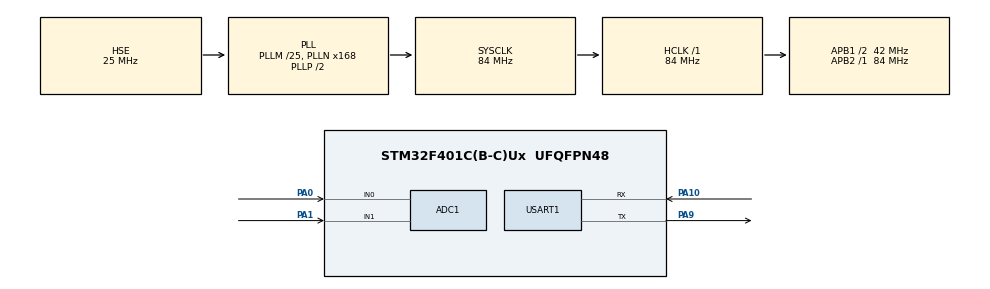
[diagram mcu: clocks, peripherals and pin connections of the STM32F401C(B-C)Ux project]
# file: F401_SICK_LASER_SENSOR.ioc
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ADC1.Channel-0\#ChannelRegularConversion=ADC_CHANNEL_0
ADC1.Channel-1\#ChannelRegularConversion=ADC_CHANNEL_1
ADC1.ContinuousConvMode=ENABLE
ADC1.NbrOfConversion=2
ADC1.NbrOfConversionFlag=1
ADC1.Rank-0\#ChannelRegularConversion=1
ADC1.Rank-1\#ChannelRegularConversion=2
ADC1.SamplingTime-0\#ChannelRegularConversion=ADC_SAMPLETIME_3CYCLES
ADC1.SamplingTime-1\#ChannelRegularConversion=ADC_SAMPLETIME_15CYCLES
ADC1.master=1
Dma.ADC1.0.Direction=DMA_PERIPH_TO_MEMORY
Dma.ADC1.0.FIFOMode=DMA_FIFOMODE_DISABLE
Dma.ADC1.0.Instance=DMA2_Stream0
Dma.ADC1.0.MemDataAlignment=DMA_MDATAALIGN_WORD
Dma.ADC1.0.MemInc=DMA_MINC_ENABLE
Dma.ADC1.0.Mode=DMA_CIRCULAR
Dma.ADC1.0.PeriphDataAlignment=DMA_PDATAALIGN_WORD
Dma.ADC1.0.PeriphInc=DMA_PINC_DISABLE
Dma.ADC1.0.Priority=DMA_PRIORITY_LOW
Dma.Request0=ADC1
Mcu.Family=STM32F4
Mcu.Name=STM32F401C(B-C)Ux
Mcu.Package=UFQFPN48
NVIC.ADC_IRQn=true\:0\:0\:false\:false\:true\:true\:true\:true
NVIC.DMA2_Stream0_IRQn=true\:0\:0\:false\:false\:true\:false\:true\:true
NVIC.PriorityGroup=NVIC_PRIORITYGROUP_4
PA0-WKUP.Signal=ADCx_IN0
PA1.Signal=ADCx_IN1
PA10.Mode=Asynchronous
PA10.Signal=USART1_RX
PA13.Mode=Serial_Wire
PA13.Signal=SYS_JTMS-SWDIO
PA14.Mode=Serial_Wire
PA14.Signal=SYS_JTCK-SWCLK
PA9.Mode=Asynchronous
PA9.Signal=USART1_TX
PH0\ -\ OSC_IN.Mode=HSE-External-Oscillator
PH0\ -\ OSC_IN.Signal=RCC_OSC_IN
PH1\ -\ OSC_OUT.Mode=HSE-External-Oscillator
PH1\ -\ OSC_OUT.Signal=RCC_OSC_OUT
ProjectManager.HeapSize=0x200
ProjectManager.StackSize=0x400
ProjectManager.TargetToolchain=STM32CubeIDE
RCC.48MHZClocksFreq_Value=42000000
RCC.AHBFreq_Value=84000000
RCC.APB1CLKDivider=RCC_HCLK_DIV2
RCC.APB1Freq_Value=42000000
RCC.APB1TimFreq_Value=84000000
RCC.APB2Freq_Value=84000000
RCC.APB2TimFreq_Value=84000000
RCC.CortexFreq_Value=84000000
RCC.HCLKFreq_Value=84000000
RCC.HSE_VALUE=25000000
RCC.HSI_VALUE=16000000
RCC.LSE_VALUE=32768
RCC.PLLM=25
RCC.PLLN=168
RCC.PLLSourceVirtual=RCC_PLLSOURCE_HSE
RCC.SYSCLKFreq_VALUE=84000000
RCC.SYSCLKSource=RCC_SYSCLKSOURCE_PLLCLK
RCC.VCOOutputFreq_Value=168000000
SH.ADCx_IN0.0=ADC1_IN0,IN0
SH.ADCx_IN1.0=ADC1_IN1,IN1
USART1.VirtualMode=VM_ASYNC
board=custom

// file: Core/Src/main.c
/* USER CODE BEGIN Header */
/**
  ******************************************************************************
  * @file           : main.c
  * @brief          : Main program body
  ******************************************************************************
  * @attention
  *
  * Copyright (c) 2024 STMicroelectronics.
  * All rights reserved.
  *
  * This software is licensed under terms that can be found in the LICENSE file
  * in the root directory of this software component.
  * If no LICENSE file comes with this software, it is provided AS-IS.
  *
  ******************************************************************************
  */
/* USER CODE END Header */
#include "main.h"
#include "adc.h"
#include "dma.h"
#include "usart.h"
#include "gpio.h"

/* USER CODE BEGIN Includes */

	float DISTANCE = 0;

/* USER CODE END Includes */

/* USER CODE BEGIN PV */

//	char msg[20];

/* USER CODE END PV */

void SystemClock_Config(void);

/* USER CODE BEGIN 0 */

		uint32_t ADC_SICK_SENSOR;
		uint32_t LASOR_SENSOR;

		/* INTERRUP MODE */

			/*

				void HAL_ADC_ConvCpltCallback(ADC_HandleTypeDef* hadc)
				{

				  ADC_SICK_SENSOR = HAL_ADC_GetValue(&hadc1);
				  // IF CONTINUOUS CONVERSION MODE IS DISABLED UNCOMMENT
				  // HAL_ADC_Start_IT (&hadc1);
				}

			*/

		/* DMA MODE */

			/*
				void HAL_ADC_ConvCpltCallback(ADC_HandleTypeDef* hadc)
				{

					ADC_SICK_SENSOR = LASOR_SENSOR; // STORE THE VALUE IN ADC_SICK_SENSOR

				}
			*/

/* USER CODE END 0 */

int main(void)
{

  /* MCU Configuration--------------------------------------------------------*/

  /* Reset of all peripherals, Initializes the Flash interface and the Systick. */
  HAL_Init();

  /* Configure the system clock */
  SystemClock_Config();

  /* Initialize all configured peripherals */
  MX_GPIO_Init();
  MX_DMA_Init();
  MX_ADC1_Init();
  MX_USART1_UART_Init();
  /* USER CODE BEGIN 2 */

	   /* INTERRUP MODE */

			  /*
				   HAL_ADC_Start_IT(&hadc1); // START TH DMA IN THE INTERRUP MODE
			  */

	   /* DMA MODE */

			   /*
				   HAL_ADC_Start_DMA(&hadc1, &LASOR_SENSOR, 1); // START IN DMA MODE AND WE ARE READ ONLY ONE CHANNEL OR ONE WORD
			   */

  /* USER CODE END 2 */

  /* Infinite loop */
  while (1)
  {

    /* USER CODE BEGIN 3 */

		  /* ADC MODE */

				  HAL_ADC_Start(&hadc1); /* START THE ADC */
				  HAL_ADC_PollForConversion(&hadc1, 100); /* WAIT FOR THE CONVERTION TO COMPLTEE */
				  ADC_SICK_SENSOR = HAL_ADC_GetValue(&hadc1); /* GET THE VALUE */
				  HAL_ADC_Stop(&hadc1); /* STOP ADC */
				  HAL_Delay(200); /* WAIT FOR SOME TIME BEFORE STARTING THE ADC AGAIN */

  }
  /* USER CODE END 3 */
}

void SystemClock_Config(void)
{
  RCC_OscInitTypeDef RCC_OscInitStruct = {0};
  RCC_ClkInitTypeDef RCC_ClkInitStruct = {0};

  /** Configure the main internal regulator output voltage
  */
  __HAL_RCC_PWR_CLK_ENABLE();
  __HAL_PWR_VOLTAGESCALING_CONFIG(PWR_REGULATOR_VOLTAGE_SCALE2);

  /** Initializes the RCC Oscillators according to the specified parameters
  * in the RCC_OscInitTypeDef structure.
  */
  RCC_OscInitStruct.OscillatorType = RCC_OSCILLATORTYPE_HSE;
  RCC_OscInitStruct.HSEState = RCC_HSE_ON;
  RCC_OscInitStruct.PLL.PLLState = RCC_PLL_ON;
  RCC_OscInitStruct.PLL.PLLSource = RCC_PLLSOURCE_HSE;
  RCC_OscInitStruct.PLL.PLLM = 25;
  RCC_OscInitStruct.PLL.PLLN = 168;
  RCC_OscInitStruct.PLL.PLLP = RCC_PLLP_DIV2;
  RCC_OscInitStruct.PLL.PLLQ = 4;
  if (HAL_RCC_OscConfig(&RCC_OscInitStruct) != HAL_OK)
  {
    Error_Handler();
  }

  /** Initializes the CPU, AHB and APB buses clocks
  */
  RCC_ClkInitStruct.ClockType = RCC_CLOCKTYPE_HCLK|RCC_CLOCKTYPE_SYSCLK
                              |RCC_CLOCKTYPE_PCLK1|RCC_CLOCKTYPE_PCLK2;
  RCC_ClkInitStruct.SYSCLKSource = RCC_SYSCLKSOURCE_PLLCLK;
  RCC_ClkInitStruct.AHBCLKDivider = RCC_SYSCLK_DIV1;
  RCC_ClkInitStruct.APB1CLKDivider = RCC_HCLK_DIV2;
  RCC_ClkInitStruct.APB2CLKDivider = RCC_HCLK_DIV1;

  if (HAL_RCC_ClockConfig(&RCC_ClkInitStruct, FLASH_LATENCY_2) != HAL_OK)
  {
    Error_Handler();
  }
}

void Error_Handler(void)
{
  __disable_irq();
  while (1)
  {
  }
}
